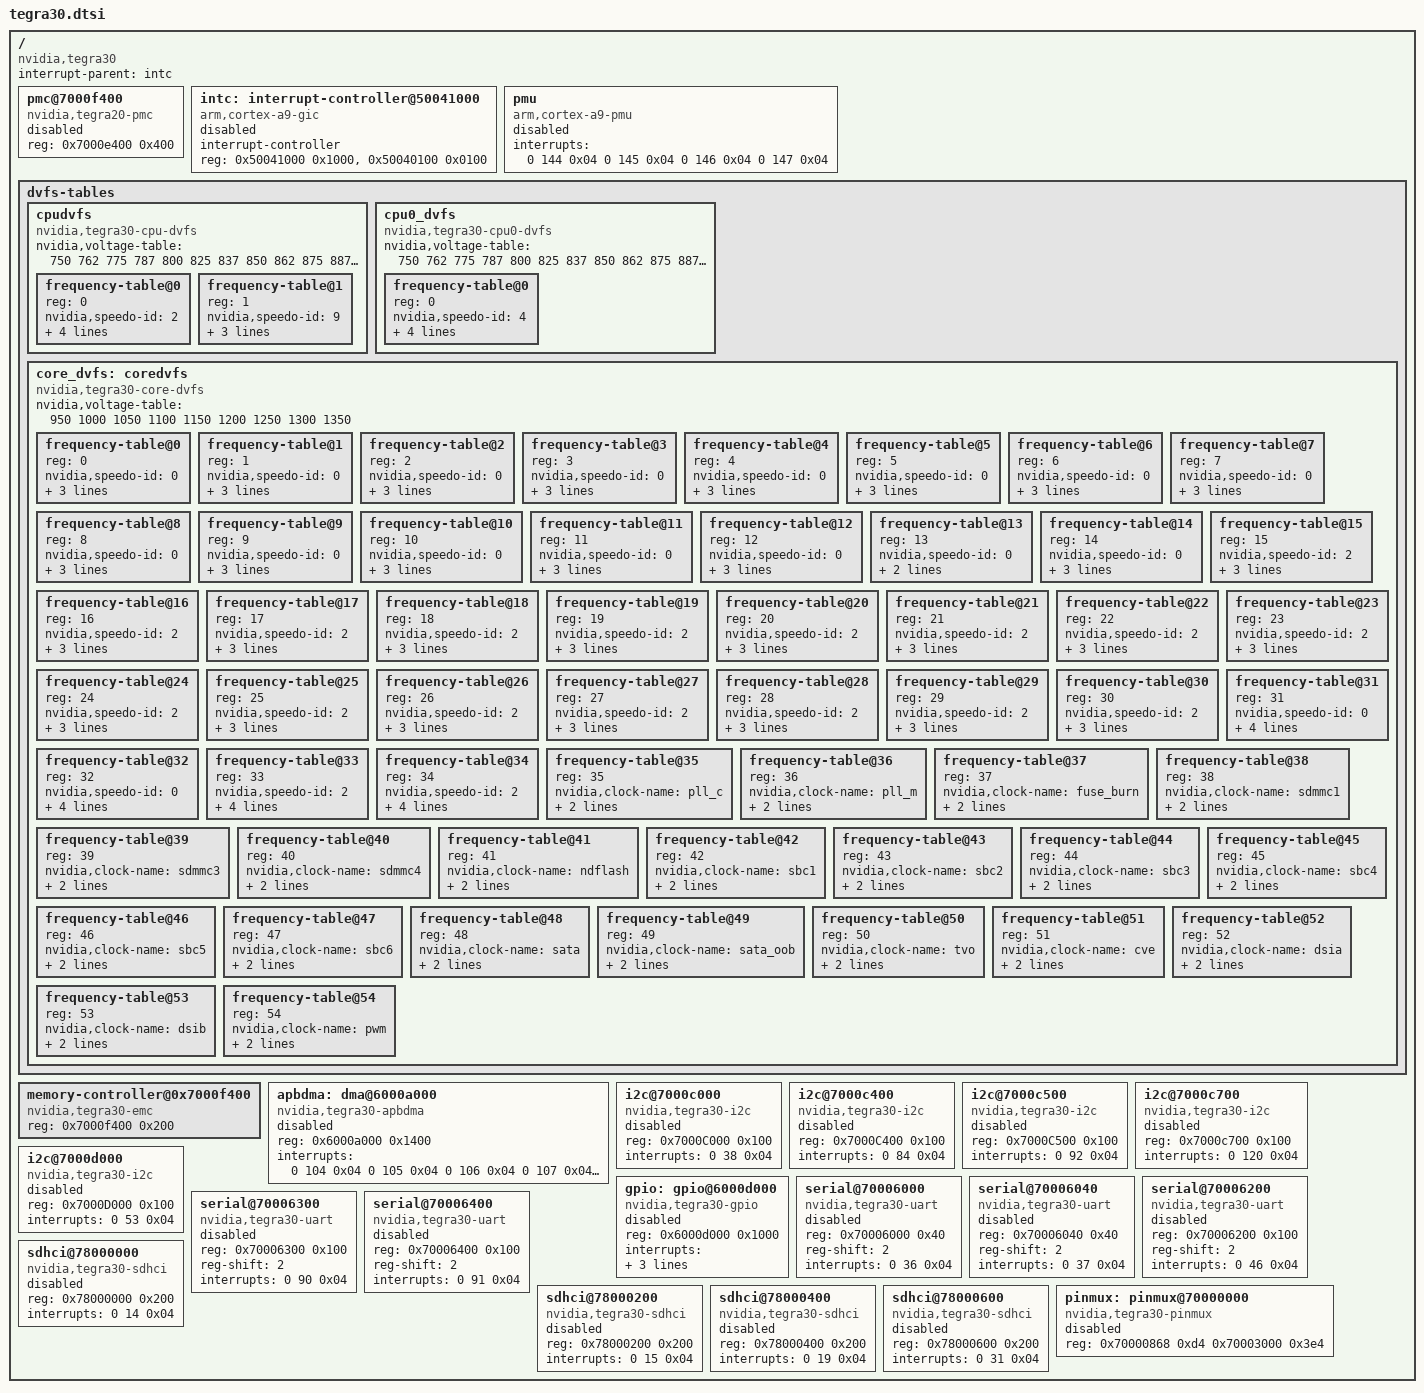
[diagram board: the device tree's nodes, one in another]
/include/ "skeleton.dtsi"

/ {
	compatible = "nvidia,tegra30";
	interrupt-parent = <&intc>;

	pmc@7000f400 {
		compatible = "nvidia,tegra20-pmc", "nvidia,tegra30-pmc";
		reg = <0x7000e400 0x400>;
		status = "disable";
	};

	intc: interrupt-controller@50041000 {
		compatible = "arm,cortex-a9-gic";
		interrupt-controller;
		#interrupt-cells = <3>;
		reg = < 0x50041000 0x1000 >,
		      < 0x50040100 0x0100 >;
		status = "disable";
	};

	pmu {
		compatible = "arm,cortex-a9-pmu";
		interrupts = <0 144 0x04
			      0 145 0x04
			      0 146 0x04
			      0 147 0x04>;
		status = "disable";
	};

	dvfs-tables {
		cpudvfs {
			compatible = "nvidia,tegra30-cpu-dvfs";
			nvidia,voltage-table = <750 762 775 787 800 825 837 850 862 875 887 900 912 916 925 937 950 962 975 987 1000 1007 1012 1025 1037 1050 1062 1075 1087 1100 1112 1125 1137 1150 1162 1175 1187 1200 1212 1237>;
			#address-cells = <0>;
			#size-cells = <1>;

			frequency-table@0 {
				reg = <0>;
				nvidia,speedo-id = <2>;
				nvidia,process-id = <2>;
				nvidia,clock-name = "cpu_g";
				nvidia,frequencies = <1000 1000 1000 1000 520000 520000 520000 700000 700000 700000 700000 860000 860000 860000 860000 860000 860000 860000 1050000 1050000 1150000 1150000 1150000 1200000 1200000 1280000 1280000 1300000 1300000 1350000 1350000 1400000>;
			};

			frequency-table@1 {
				reg = <1>;
				nvidia,speedo-id = <9>;
				nvidia,clock-name = "cpu_g";
				nvidia,frequencies = <1000 1000 1000 1000 1000 1000 1000 1000 1000 1000 1000 1000 1000 1000 1000 1000 1000 1000 1000 1000 1000 900000 900000 900000 900000 900000 900000 900000 900000 900000 900000 900000 900000 900000>;
			};
		};

		cpu0_dvfs {
			compatible = "nvidia,tegra30-cpu0-dvfs";
			nvidia,voltage-table = <750 762 775 787 800 825 837 850 862 875 887 900 912 916 925 937 950 962 975 987 1000 1007 1012 1025 1037 1050 1062 1075 1087 1100 1112 1125 1137 1150 1162 1175 1187 1200 1212 1237>;
			#address-cells = <0>;
			#size-cells = <1>;

			frequency-table@0 {
				reg = <0>;
				nvidia,speedo-id = <4>;
				nvidia,process-id = <0>;
				nvidia,clock-name = "cpu0";
				nvidia,frequencies = <1000 1000 1000 475000 475000 475000 475000 640000 640000 640000 760000 760000 760000 760000 860000 860000 860000 860000 860000 1000000 1000000 1000000 1000000 1100000 1100000 1100000 1100000 1200000 1200000 1200000 1200000 1200000 1300000 1300000 1300000 1300000 1400000 1400000 1400000 1500000>;
			};
		};

		core_dvfs: coredvfs {
			compatible = "nvidia,tegra30-core-dvfs";
			nvidia,voltage-table = <950 1000 1050 1100 1150 1200 1250 1300 1350>;
			#address-cells = <0>;
			#size-cells = <1>;

			frequency-table@0 {
				reg = <0>;
				nvidia,speedo-id = <0>;
				nvidia,clock-name = "cpu_lp";
				nvidia,frequencies = <1 294000 342000 427000 475000 500000 500000 500000 500000>;
			};

			frequency-table@1 {
				reg = <1>;
				nvidia,speedo-id = <0>;
				nvidia,clock-name = "emc";
				nvidia,frequencies = <1 266500 266500 266500 266500 533000 533000 533000 533000>;
			};

			frequency-table@2 {
				reg = <2>;
				nvidia,speedo-id = <0>;
				nvidia,clock-name = "sbus";
				nvidia,frequencies = <1 136000 164000 191000 216000 216000 216000 216000 216000>;
			};

			frequency-table@3 {
				reg = <3>;
				nvidia,speedo-id = <0>;
				nvidia,clock-name = "vi";
				nvidia,frequencies = <1 216000 285000 300000 300000 300000 300000 300000 300000>;
			};

			frequency-table@4 {
				reg = <4>;
				nvidia,speedo-id = <0>;
				nvidia,clock-name = "vde";
				nvidia,frequencies = <1 228000 275000 332000 380000 416000 416000 416000 416000>;
			};

			frequency-table@5 {
				reg = <5>;
				nvidia,speedo-id = <0>;
				nvidia,clock-name = "mpe";
				nvidia,frequencies = <1 234000 285000 332000 380000 416000 416000 416000 416000>;
			};

			frequency-table@6 {
				reg = <6>;
				nvidia,speedo-id = <0>;
				nvidia,clock-name = "2d";
				nvidia,frequencies = <1 267000 285000 332000 380000 416000 416000 416000 416000>;
			};

			frequency-table@7 {
				reg = <7>;
				nvidia,speedo-id = <0>;
				nvidia,clock-name = "epp";
				nvidia,frequencies = <1 267000 285000 332000 380000 416000 416000 416000 416000>;
			};

			frequency-table@8 {
				reg = <8>;
				nvidia,speedo-id = <0>;
				nvidia,clock-name = "3d";
				nvidia,frequencies = <1 234000 285000 332000 380000 416000 416000 416000 416000>;
			};

			frequency-table@9 {
				reg = <9>;
				nvidia,speedo-id = <0>;
				nvidia,clock-name = "3d2";
				nvidia,frequencies = <1 234000 285000 332000 380000 416000 416000 416000 416000>;
			};

			frequency-table@10 {
				reg = <10>;
				nvidia,speedo-id = <0>;
				nvidia,clock-name = "se";
				nvidia,frequencies = <1 267000 285000 332000 380000 416000 416000 416000 416000>;
			};

			frequency-table@11 {
				reg = <11>;
				nvidia,speedo-id = <0>;
				nvidia,clock-name = "host1x";
				nvidia,frequencies = <1 152000 188000 222000 254000 267000 267000 267000 267000>;
			};

			frequency-table@12 {
				reg = <12>;
				nvidia,speedo-id = <0>;
				nvidia,clock-name = "cbus";
				nvidia,frequencies = <1 228000 275000 332000 380000 416000 416000 416000 416000>;
			};

			frequency-table@13 {
				reg = <13>;
				nvidia,speedo-id = <0>;
				nvidia,clock-name = "mipi";
				nvidia,frequencies = <1 1 1 1 1 1 1 1 1>;
			};

			frequency-table@14 {
				reg = <14>;
				nvidia,speedo-id = <0>;
				nvidia,clock-name = "nor";
				nvidia,frequencies = <1 115000 130000 130000 133000 133000 133000 133000 133000>;
			};

			frequency-table@15 {
				reg = <15>;
				nvidia,speedo-id = <2>;
				nvidia,clock-name = "cpu_lp";
				nvidia,frequencies = <204000 295000 370000 428000 475000 513000 579000 620000 620000>;
			};

			frequency-table@16 {
				reg = <16>;
				nvidia,speedo-id = <2>;
				nvidia,clock-name = "emc";
				nvidia,frequencies = <102000 450000 450000 450000 450000 667000 667000 800000 900000>;
			};

			frequency-table@17 {
				reg = <17>;
				nvidia,speedo-id = <2>;
				nvidia,clock-name = "sbus";
				nvidia,frequencies = <102000 205000 205000 227000 227000 267000 334000 334000 334000>;
			};

			frequency-table@18 {
				reg = <18>;
				nvidia,speedo-id = <2>;
				nvidia,clock-name = "vi";
				nvidia,frequencies = <1 219000 267000 300000 371000 409000 425000 425000 425000>;
			};

			frequency-table@19 {
				reg = <19>;
				nvidia,speedo-id = <2>;
				nvidia,clock-name = "vde";
				nvidia,frequencies = <200000 247000 304000 352000 400000 437000 484000 520000 600000>;
			};

			frequency-table@20 {
				reg = <20>;
				nvidia,speedo-id = <2>;
				nvidia,clock-name = "mpe";
				nvidia,frequencies = <200000 247000 304000 361000 408000 446000 484000 520000 600000>;
			};

			frequency-table@21 {
				reg = <21>;
				nvidia,speedo-id = <2>;
				nvidia,clock-name = "2d";
				nvidia,frequencies = <200000 267000 304000 361000 408000 446000 484000 520000 600000>;
			};

			frequency-table@22 {
				reg = <22>;
				nvidia,speedo-id = <2>;
				nvidia,clock-name = "epp";
				nvidia,frequencies = <200000 267000 304000 361000 408000 446000 484000 520000 600000>;
			};

			frequency-table@23 {
				reg = <23>;
				nvidia,speedo-id = <2>;
				nvidia,clock-name = "3d";
				nvidia,frequencies = <200000 247000 304000 361000 408000 446000 484000 520000 600000>;
			};

			frequency-table@24 {
				reg = <24>;
				nvidia,speedo-id = <2>;
				nvidia,clock-name = "3d2";
				nvidia,frequencies = <200000 247000 304000 361000 408000 446000 484000 520000 600000>;
			};

			frequency-table@25 {
				reg = <25>;
				nvidia,speedo-id = <2>;
				nvidia,clock-name = "se";
				nvidia,frequencies = <200000 267000 304000 361000 408000 446000 484000 520000 600000>;
			};

			frequency-table@26 {
				reg = <26>;
				nvidia,speedo-id = <2>;
				nvidia,clock-name = "host1x";
				nvidia,frequencies = <100000 152000 188000 222000 254000 267000 267000 267000 300000>;
			};

			frequency-table@27 {
				reg = <27>;
				nvidia,speedo-id = <2>;
				nvidia,clock-name = "cbus";
				nvidia,frequencies = <200000 247000 304000 352000 400000 437000 484000 520000 600000>;
			};

			frequency-table@28 {
				reg = <28>;
				nvidia,speedo-id = <2>;
				nvidia,clock-name = "mipi";
				nvidia,frequencies = <1 1 1 1 1 60000 60000 60000 60000>;
			};

			frequency-table@29 {
				reg = <29>;
				nvidia,speedo-id = <2>;
				nvidia,clock-name = "nor";
				nvidia,frequencies = <102000 115000 130000 130000 133000 133000 133000 133000 133000>;
			};

			frequency-table@30 {
				reg = <30>;
				nvidia,speedo-id = <2>;
				nvidia,clock-name = "pll_m";
				nvidia,frequencies = <533000 900000 900000 900000 900000 1066000 1066000 1066000 1066000>;
			};

			frequency-table@31 {
				reg = <31>;
				nvidia,speedo-id = <0>;
				nvidia,clock-name = "disp1";
				nvidia,manual-dvfs;
				nvidia,frequencies = <1000 120000 120000 120000 120000 190000 190000 190000 190000>;
			};

			frequency-table@32 {
				reg = <32>;
				nvidia,speedo-id = <0>;
				nvidia,clock-name = "disp2";
				nvidia,manual-dvfs;
				nvidia,frequencies = <1000 120000 120000 120000 120000 190000 190000 190000 190000>;
			};

			frequency-table@33 {
				reg = <33>;
				nvidia,speedo-id = <2>;
				nvidia,clock-name = "disp1";
				nvidia,manual-dvfs;
				nvidia,frequencies = <155000 155000 268000 268000 268000 268000 268000 268000 268000>;
			};

			frequency-table@34 {
				reg = <34>;
				nvidia,speedo-id = <2>;
				nvidia,clock-name = "disp2";
				nvidia,manual-dvfs;
				nvidia,frequencies = <155000 155000 268000 268000 268000 268000 268000 268000 268000>;
			};

			frequency-table@35 {
				reg = <35>;
				nvidia,clock-name = "pll_c";
				nvidia,frequencies = <533000 667000 667000 800000 800000 1066000 1066000 1066000 1200000>;
			};

			frequency-table@36 {
				reg = <36>;
				nvidia,clock-name = "pll_m";
				nvidia,frequencies = <533000 667000 667000 800000 800000 1066000 1066000 1066000 1066000>;
			};

			frequency-table@37 {
				reg = <37>;
				nvidia,clock-name = "fuse_burn";
				nvidia,frequencies = <1 1 1 1 26000 26000 26000 26000 26000>;
			};

			frequency-table@38 {
				reg = <38>;
				nvidia,clock-name = "sdmmc1";
				nvidia,frequencies = <104000 104000 104000 104000 104000 208000 208000 208000 208000>;
			};

			frequency-table@39 {
				reg = <39>;
				nvidia,clock-name = "sdmmc3";
				nvidia,frequencies = <104000 104000 104000 104000 104000 208000 208000 208000 208000>;
			};

			frequency-table@40 {
				reg = <40>;
				nvidia,clock-name = "sdmmc4";
				nvidia,frequencies = <51000 102000 102000 102000 102000 102000 102000 102000 102000>;
			};

			frequency-table@41 {
				reg = <41>;
				nvidia,clock-name = "ndflash";
				nvidia,frequencies = <120000 120000 120000 120000 200000 200000 200000 200000 200000>;
			};

			frequency-table@42 {
				reg = <42>;
				nvidia,clock-name = "sbc1";
				nvidia,frequencies = <36000 52000 60000 60000 60000 100000 100000 100000 100000>;
			};

			frequency-table@43 {
				reg = <43>;
				nvidia,clock-name = "sbc2";
				nvidia,frequencies = <36000 52000 60000 60000 60000 100000 100000 100000 100000>;
			};

			frequency-table@44 {
				reg = <44>;
				nvidia,clock-name = "sbc3";
				nvidia,frequencies = <36000 52000 60000 60000 60000 100000 100000 100000 100000>;
			};

			frequency-table@45 {
				reg = <45>;
				nvidia,clock-name = "sbc4";
				nvidia,frequencies = <36000 52000 60000 60000 60000 100000 100000 100000 100000>;
			};

			frequency-table@46 {
				reg = <46>;
				nvidia,clock-name = "sbc5";
				nvidia,frequencies = <36000 52000 60000 60000 60000 100000 100000 100000 100000>;
			};

			frequency-table@47 {
				reg = <47>;
				nvidia,clock-name = "sbc6";
				nvidia,frequencies = <36000 52000 60000 60000 60000 100000 100000 100000 100000>;
			};

			frequency-table@48 {
				reg = <48>;
				nvidia,clock-name = "sata";
				nvidia,frequencies = <1 216000 216000 216000 216000 216000 216000 216000 216000>;
			};

			frequency-table@49 {
				reg = <49>;
				nvidia,clock-name = "sata_oob";
				nvidia,frequencies = <1 216000 216000 216000 216000 216000 216000 216000 216000>;
			};

			frequency-table@50 {
				reg = <50>;
				nvidia,clock-name = "tvo";
				nvidia,frequencies = <1 1 297000 297000 297000 297000 297000 297000 297000>;
			};

			frequency-table@51 {
				reg = <51>;
				nvidia,clock-name = "cve";
				nvidia,frequencies = <1 1 297000 297000 297000 297000 297000 297000 297000>;
			};

			frequency-table@52 {
				reg = <52>;
				nvidia,clock-name = "dsia";
				nvidia,frequencies = <432500 432500 432500 432500 432500 432500 432500 432500 432500>;
			};

			frequency-table@53 {
				reg = <53>;
				nvidia,clock-name = "dsib";
				nvidia,frequencies = <432500 432500 432500 432500 432500 432500 432500 432500 432500>;
			};

			frequency-table@54 {
				reg = <54>;
				nvidia,clock-name = "pwm";
				nvidia,frequencies = <204000 408000 408000 408000 408000 408000 408000 408000 408000>;
			};
		};
	};

	memory-controller@0x7000f400 {
		compatible = "nvidia,tegra30-emc";
		reg = <0x7000f400 0x200>;
		#address-cells = <1>;
		#size-cells = <0>;
	};

	apbdma: dma@6000a000 {
		compatible = "nvidia,tegra30-apbdma", "nvidia,tegra20-apbdma";
		reg = <0x6000a000 0x1400>;
		interrupts = < 0 104 0x04
			       0 105 0x04
			       0 106 0x04
			       0 107 0x04
			       0 108 0x04
			       0 109 0x04
			       0 110 0x04
			       0 111 0x04
			       0 112 0x04
			       0 113 0x04
			       0 114 0x04
			       0 115 0x04
			       0 116 0x04
			       0 117 0x04
			       0 118 0x04
			       0 119 0x04
			       0 128 0x04
			       0 129 0x04
			       0 130 0x04
			       0 131 0x04
			       0 132 0x04
			       0 133 0x04
			       0 134 0x04
			       0 135 0x04
			       0 136 0x04
			       0 137 0x04
			       0 138 0x04
			       0 139 0x04
			       0 140 0x04
			       0 141 0x04
			       0 142 0x04
			       0 143 0x04 >;
		status = "disable";
	};

	i2c@7000c000 {
		#address-cells = <1>;
		#size-cells = <0>;
		compatible =  "nvidia,tegra30-i2c", "nvidia,tegra20-i2c";
		reg = <0x7000C000 0x100>;
		interrupts = < 0 38 0x04 >;
		status = "disable";
	};

	i2c@7000c400 {
		#address-cells = <1>;
		#size-cells = <0>;
		compatible = "nvidia,tegra30-i2c", "nvidia,tegra20-i2c";
		reg = <0x7000C400 0x100>;
		interrupts = < 0 84 0x04 >;
		status = "disable";
	};

	i2c@7000c500 {
		#address-cells = <1>;
		#size-cells = <0>;
		compatible = "nvidia,tegra30-i2c", "nvidia,tegra20-i2c";
		reg = <0x7000C500 0x100>;
		interrupts = < 0 92 0x04 >;
		status = "disable";
	};

	i2c@7000c700 {
		#address-cells = <1>;
		#size-cells = <0>;
		compatible = "nvidia,tegra30-i2c", "nvidia,tegra20-i2c";
		reg = <0x7000c700 0x100>;
		interrupts = < 0 120 0x04 >;
		status = "disable";
	};

	i2c@7000d000 {
		#address-cells = <1>;
		#size-cells = <0>;
		compatible = "nvidia,tegra30-i2c", "nvidia,tegra20-i2c";
		reg = <0x7000D000 0x100>;
		interrupts = < 0 53 0x04 >;
		status = "disable";
	};

	gpio: gpio@6000d000 {
		compatible = "nvidia,tegra30-gpio", "nvidia,tegra20-gpio";
		reg = < 0x6000d000 0x1000 >;
		interrupts = < 0 32 0x04
			       0 33 0x04
			       0 34 0x04
			       0 35 0x04
			       0 55 0x04
			       0 87 0x04
			       0 89 0x04
			       0 125 0x04 >;
		#gpio-cells = <2>;
		gpio-controller;
		#interrupt-cells = <2>;
		interrupt-controller;
		status = "disable";
	};

	serial@70006000 {
		compatible = "nvidia,tegra30-uart", "nvidia,tegra20-uart";
		reg = <0x70006000 0x40>;
		reg-shift = <2>;
		interrupts = < 0 36 0x04 >;
		status = "disable";
	};

	serial@70006040 {
		compatible = "nvidia,tegra30-uart", "nvidia,tegra20-uart";
		reg = <0x70006040 0x40>;
		reg-shift = <2>;
		interrupts = < 0 37 0x04 >;
		status = "disable";
	};

	serial@70006200 {
		compatible = "nvidia,tegra30-uart", "nvidia,tegra20-uart";
		reg = <0x70006200 0x100>;
		reg-shift = <2>;
		interrupts = < 0 46 0x04 >;
		status = "disable";
	};

	serial@70006300 {
		compatible = "nvidia,tegra30-uart", "nvidia,tegra20-uart";
		reg = <0x70006300 0x100>;
		reg-shift = <2>;
		interrupts = < 0 90 0x04 >;
		status = "disable";
	};

	serial@70006400 {
		compatible = "nvidia,tegra30-uart", "nvidia,tegra20-uart";
		reg = <0x70006400 0x100>;
		reg-shift = <2>;
		interrupts = < 0 91 0x04 >;
		status = "disable";
	};

	sdhci@78000000 {
		compatible = "nvidia,tegra30-sdhci", "nvidia,tegra20-sdhci";
		reg = <0x78000000 0x200>;
		interrupts = < 0 14 0x04 >;
		status = "disable";
	};

	sdhci@78000200 {
		compatible = "nvidia,tegra30-sdhci", "nvidia,tegra20-sdhci";
		reg = <0x78000200 0x200>;
		interrupts = < 0 15 0x04 >;
		status = "disable";
	};

	sdhci@78000400 {
		compatible = "nvidia,tegra30-sdhci", "nvidia,tegra20-sdhci";
		reg = <0x78000400 0x200>;
		interrupts = < 0 19 0x04 >;
		status = "disable";
	};

	sdhci@78000600 {
		compatible = "nvidia,tegra30-sdhci", "nvidia,tegra20-sdhci";
		reg = <0x78000600 0x200>;
		interrupts = < 0 31 0x04 >;
		status = "disable";
	};

	pinmux: pinmux@70000000 {
		compatible = "nvidia,tegra30-pinmux";
		reg = < 0x70000868 0xd4     /* Pad control registers */
			0x70003000 0x3e4 >; /* Mux registers */
		status = "disable";
	};
};
